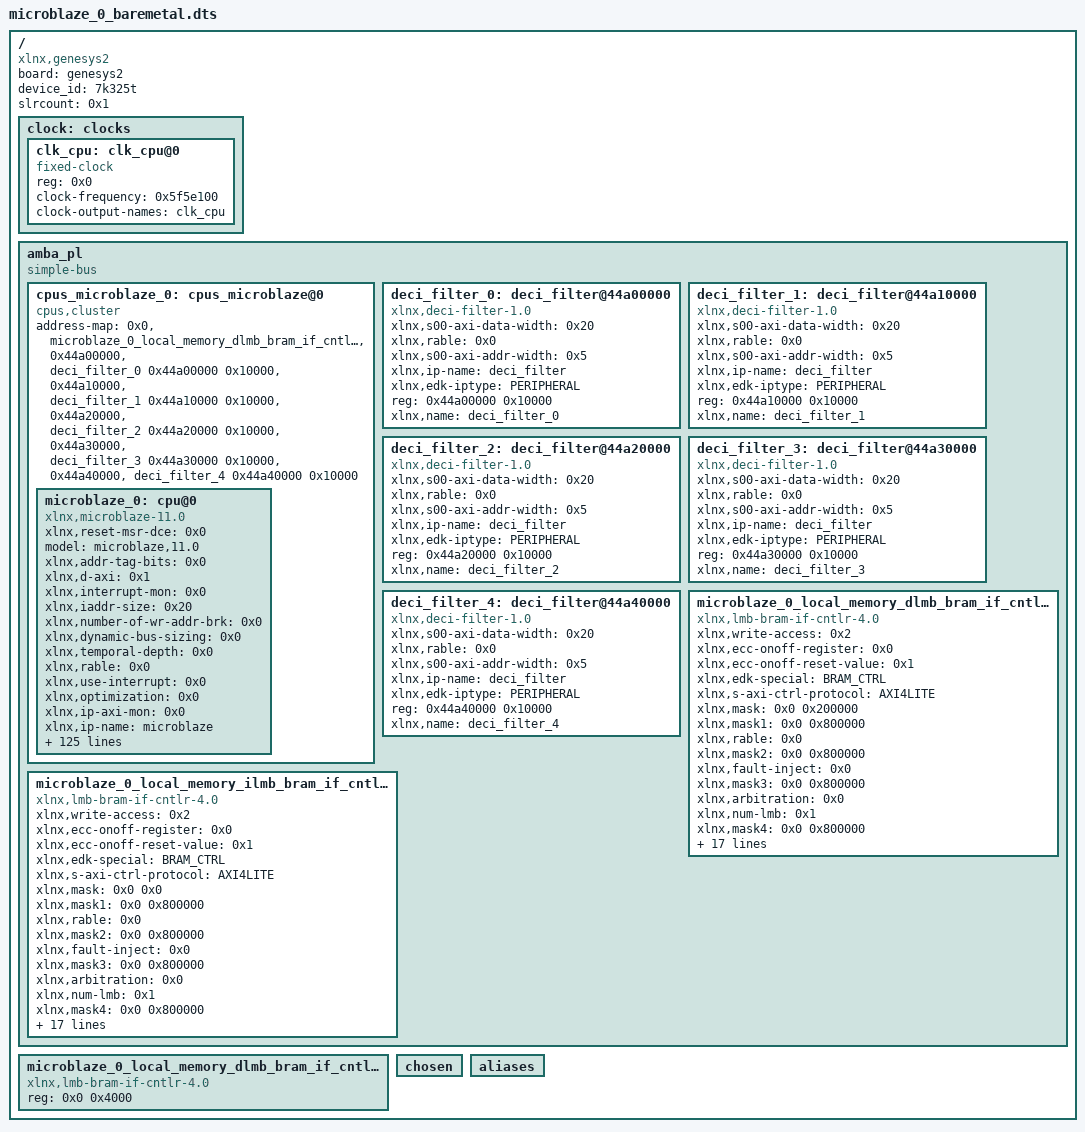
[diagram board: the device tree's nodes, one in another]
/dts-v1/;

/ {
        board = "genesys2";
        compatible = "xlnx,genesys2";
        device_id = "7k325t";
        #address-cells = <0x1>;
        #size-cells = <0x1>;
        slrcount = <0x1>;

        clock: clocks {
                #address-cells = <0x1>;
                #size-cells = <0x0>;
                phandle = <0x8>;

                clk_cpu: clk_cpu@0 {
                        compatible = "fixed-clock";
                        reg = <0x0>;
                        clock-frequency = <0x5f5e100>;
                        clock-output-names = "clk_cpu";
                        #clock-cells = <0x0>;
                        phandle = <0x9>;
                };
        };

        amba_pl: amba_pl {
                ranges;
                compatible = "simple-bus";
                #address-cells = <0x1>;
                #size-cells = <0x1>;
                phandle = <0x7>;

                cpus_microblaze_0: cpus_microblaze@0 {
                        #cpu-mask-cells = <0x1>;
                        compatible = "cpus,cluster";
                        address-map = <0x0 &microblaze_0_local_memory_dlmb_bram_if_cntlr_memory 0x0 0x4000>,
                         <0x44a00000 &deci_filter_0 0x44a00000 0x10000>,
                         <0x44a10000 &deci_filter_1 0x44a10000 0x10000>,
                         <0x44a20000 &deci_filter_2 0x44a20000 0x10000>,
                         <0x44a30000 &deci_filter_3 0x44a30000 0x10000>,
                         <0x44a40000 &deci_filter_4 0x44a40000 0x10000>;
                        #ranges-address-cells = <0x1>;
                        #ranges-size-cells = <0x1>;
                        phandle = <0xa>;

                        microblaze_0: cpu@0 {
                                xlnx,reset-msr-dce = <0x0>;
                                model = "microblaze,11.0";
                                xlnx,addr-tag-bits = <0x0>;
                                xlnx,d-axi = <0x1>;
                                xlnx,interrupt-mon = <0x0>;
                                xlnx,iaddr-size = <0x20>;
                                xlnx,number-of-wr-addr-brk = <0x0>;
                                xlnx,dynamic-bus-sizing = <0x0>;
                                xlnx,temporal-depth = <0x0>;
                                xlnx,rable = <0x0>;
                                xlnx,use-interrupt = <0x0>;
                                xlnx,optimization = <0x0>;
                                xlnx,ip-axi-mon = <0x0>;
                                xlnx,ip-name = "microblaze";
                                d-cache-highaddr = <0x3fffffff>;
                                xlnx,dcache-force-tag-lutram = <0x0>;
                                xlnx,pc-width = <0x20>;
                                xlnx,interrupt-is-edge = <0x0>;
                                reg = <0x0>;
                                xlnx,async-interrupt = <0x1>;
                                xlnx,use-mmu = <0x0>;
                                xlnx,reset-msr-ee = <0x0>;
                                xlnx,icache-victims = <0x0>;
                                xlnx,use-reorder-instr = <0x1>;
                                xlnx,d-lmb-mon = <0x0>;
                                xlnx,d-lmb-protocol = <0x0>;
                                xlnx,ill-opcode-exception = <0x0>;
                                xlnx,dcache-always-used = <0x1>;
                                xlnx,use-div = <0x0>;
                                xlnx,dc-axi-mon = <0x0>;
                                xlnx,debug-trace-async-reset = <0x0>;
                                xlnx,trace = <0x0>;
                                xlnx,part = "xc7k325tffg900-2";
                                i-cache-baseaddr = <0x0>;
                                xlnx,use-config-reset = <0x0>;
                                xlnx,pvr = <0x0>;
                                xlnx,i-lmb-mon = <0x0>;
                                xlnx,dcache-byte-size = <0x2000>;
                                xlnx,fault-tolerant = <0x0>;
                                xlnx,family = "kintex7";
                                compatible = "xlnx,microblaze-11.0", "xlnx,microblaze";
                                xlnx,data-size = <0x20>;
                                xlnx,mmu-zones = <0x10>;
                                xlnx,debug-trace-size = <0x2000>;
                                xlnx,mmu-privileged-instr = <0x0>;
                                xlnx,enable-discrete-ports = <0x0>;
                                d-cache-line-size = <0x10>;
                                xlnx,d-lmb = <0x1>;
                                xlnx,sco = <0x0>;
                                xlnx,reset-msr-eip = <0x0>;
                                clock-frequency = <0x5f5e100>;
                                xlnx,debug-interface = <0x0>;
                                xlnx,use-ext-brk = <0x0>;
                                xlnx,daddr-size = <0x20>;
                                xlnx,debug-enabled = <0x1>;
                                xlnx,reset-msr-ice = <0x0>;
                                xlnx,num-sync-ff-dbg-trace-clk = <0x2>;
                                xlnx,i-lmb-protocol = <0x0>;
                                xlnx,endianness = <0x1>;
                                xlnx,fsl-exception = <0x0>;
                                i-cache-line-size = <0x10>;
                                xlnx,use-extended-fsl-instr = <0x0>;
                                xlnx,reset-msr = <0x0>;
                                xlnx,dp-axi-mon = <0x0>;
                                xlnx,branch-target-cache-size = <0x0>;
                                xlnx,dcache-use-writeback = <0x0>;
                                xlnx,div-zero-exception = <0x0>;
                                xlnx,mmu-tlb-access = <0x3>;
                                bus-handle = <0x7>;
                                xlnx,cache-byte-size = <0x2000>;
                                xlnx,pvr-user2 = <0x0>;
                                xlnx,opcode-0x0-illegal = <0x0>;
                                xlnx,icache-line-len = <0x4>;
                                xlnx,ecc-use-ce-exception = <0x0>;
                                xlnx,base-vectors = <0x0 0x0>;
                                xlnx,use-dcache = <0x0>;
                                xlnx,use-barrel = <0x0>;
                                xlnx,reset-msr-bip = <0x0>;
                                xlnx,edk-special = "microblaze";
                                xlnx,allow-dcache-wr = <0x1>;
                                xlnx,addr-size = <0x20>;
                                xlnx,debug-external-trace = <0x0>;
                                xlnx,piaddr-size = <0x20>;
                                i-cache-highaddr = <0x3fffffff>;
                                xlnx,num-sync-ff-clk-debug = <0x2>;
                                xlnx,debug-event-counters = <0x5>;
                                xlnx,fpu-exception = <0x0>;
                                xlnx,allow-icache-wr = <0x1>;
                                xlnx,i-axi = <0x0>;
                                xlnx,g-use-exceptions = <0x0>;
                                xlnx,icache-streams = <0x0>;
                                xlnx,g-template-list = <0x0>;
                                xlnx,dcache-line-len = <0x4>;
                                xlnx,num-sync-ff-clk = <0x2>;
                                xlnx,use-stack-protection = <0x0>;
                                xlnx,use-hw-mul = <0x0>;
                                xlnx,num-sync-ff-dbg-clk = <0x1>;
                                xlnx,interconnect = <0x2>;
                                xlnx,edk-iptype = "PROCESSOR";
                                i-cache-size = <0x2000>;
                                xlnx,debug-latency-counters = <0x1>;
                                xlnx,use-fpu = <0x0>;
                                xlnx,reset-msr-ie = <0x0>;
                                xlnx,edge-is-positive = <0x1>;
                                xlnx,use-pcmp-instr = <0x0>;
                                xlnx,use-icache = <0x0>;
                                d-cache-size = <0x2000>;
                                xlnx,async-wakeup = <0x3>;
                                xlnx,use-non-secure = <0x0>;
                                xlnx,dcache-addr-tag = <0x0>;
                                xlnx,number-of-rd-addr-brk = <0x0>;
                                d-cache-baseaddr = <0x0>;
                                xlnx,area-optimized = <0x0>;
                                xlnx,avoid-primitives = <0x0>;
                                xlnx,lockstep-slave = <0x0>;
                                xlnx,use-ext-nm-brk = <0x0>;
                                xlnx,instr-size = <0x20>;
                                xlnx,icache-always-used = <0x1>;
                                xlnx,i-lmb = <0x1>;
                                xlnx,mmu-dtlb-size = <0x4>;
                                xlnx,lockstep-select = <0x0>;
                                xlnx,lmb-data-size = <0x20>;
                                xlnx,ic-axi-mon = <0x0>;
                                xlnx,num-sync-ff-clk-irq = <0x1>;
                                xlnx,fsl-links = <0x0>;
                                timebase-frequency = <0x5f5e100>;
                                xlnx,icache-force-tag-lutram = <0x0>;
                                xlnx,dcache-data-width = <0x0>;
                                xlnx,dcache-victims = <0x0>;
                                xlnx,use-branch-target-cache = <0x0>;
                                xlnx,debug-profile-size = <0x0>;
                                xlnx,unaligned-exceptions = <0x0>;
                                xlnx,lockstep-master = <0x0>;
                                xlnx,freq = <0x5f5e100>;
                                xlnx,number-of-pc-brk = <0x1>;
                                xlnx,mmu-itlb-size = <0x2>;
                                xlnx,imprecise-exceptions = <0x0>;
                                xlnx,use-msr-instr = <0x0>;
                                xlnx,icache-data-width = <0x0>;
                                xlnx,debug-counter-width = <0x20>;
                                phandle = <0xb>;
                        };
                };

                deci_filter_0: deci_filter@44a00000 {
                        xlnx,s00-axi-data-width = <0x20>;
                        xlnx,rable = <0x0>;
                        compatible = "xlnx,deci-filter-1.0";
                        status = "okay";
                        xlnx,s00-axi-addr-width = <0x5>;
                        xlnx,ip-name = "deci_filter";
                        xlnx,edk-iptype = "PERIPHERAL";
                        reg = <0x44a00000 0x10000>;
                        xlnx,name = "deci_filter_0";
                        phandle = <0x2>;
                };

                deci_filter_1: deci_filter@44a10000 {
                        xlnx,s00-axi-data-width = <0x20>;
                        xlnx,rable = <0x0>;
                        compatible = "xlnx,deci-filter-1.0";
                        status = "okay";
                        xlnx,s00-axi-addr-width = <0x5>;
                        xlnx,ip-name = "deci_filter";
                        xlnx,edk-iptype = "PERIPHERAL";
                        reg = <0x44a10000 0x10000>;
                        xlnx,name = "deci_filter_1";
                        phandle = <0x3>;
                };

                deci_filter_2: deci_filter@44a20000 {
                        xlnx,s00-axi-data-width = <0x20>;
                        xlnx,rable = <0x0>;
                        compatible = "xlnx,deci-filter-1.0";
                        status = "okay";
                        xlnx,s00-axi-addr-width = <0x5>;
                        xlnx,ip-name = "deci_filter";
                        xlnx,edk-iptype = "PERIPHERAL";
                        reg = <0x44a20000 0x10000>;
                        xlnx,name = "deci_filter_2";
                        phandle = <0x4>;
                };

                deci_filter_3: deci_filter@44a30000 {
                        xlnx,s00-axi-data-width = <0x20>;
                        xlnx,rable = <0x0>;
                        compatible = "xlnx,deci-filter-1.0";
                        status = "okay";
                        xlnx,s00-axi-addr-width = <0x5>;
                        xlnx,ip-name = "deci_filter";
                        xlnx,edk-iptype = "PERIPHERAL";
                        reg = <0x44a30000 0x10000>;
                        xlnx,name = "deci_filter_3";
                        phandle = <0x5>;
                };

                deci_filter_4: deci_filter@44a40000 {
                        xlnx,s00-axi-data-width = <0x20>;
                        xlnx,rable = <0x0>;
                        compatible = "xlnx,deci-filter-1.0";
                        status = "okay";
                        xlnx,s00-axi-addr-width = <0x5>;
                        xlnx,ip-name = "deci_filter";
                        xlnx,edk-iptype = "PERIPHERAL";
                        reg = <0x44a40000 0x10000>;
                        xlnx,name = "deci_filter_4";
                        phandle = <0x6>;
                };

                microblaze_0_local_memory_dlmb_bram_if_cntlr: lmb_bram_if_cntlr@0 {
                        xlnx,write-access = <0x2>;
                        compatible = "xlnx,lmb-bram-if-cntlr-4.0";
                        xlnx,ecc-onoff-register = <0x0>;
                        xlnx,ecc-onoff-reset-value = <0x1>;
                        xlnx,edk-special = "BRAM_CTRL";
                        xlnx,s-axi-ctrl-protocol = "AXI4LITE";
                        xlnx,mask = <0x0 0x200000>;
                        xlnx,mask1 = <0x0 0x800000>;
                        xlnx,rable = <0x0>;
                        xlnx,mask2 = <0x0 0x800000>;
                        xlnx,fault-inject = <0x0>;
                        xlnx,mask3 = <0x0 0x800000>;
                        xlnx,arbitration = <0x0>;
                        xlnx,num-lmb = <0x1>;
                        xlnx,mask4 = <0x0 0x800000>;
                        reg = <0x0 0x4000>;
                        xlnx,s-axi-ctrl-addr-width = <0x20>;
                        xlnx,mask5 = <0x0 0x800000>;
                        xlnx,ecc-status-registers = <0x0>;
                        xlnx,mask6 = <0x0 0x800000>;
                        xlnx,lmb-protocol = <0x0>;
                        xlnx,ce-counter-width = <0x0>;
                        xlnx,mask7 = <0x0 0x800000>;
                        xlnx,ecc = <0x0>;
                        xlnx,lmb-dwidth = <0x20>;
                        xlnx,interconnect = <0x0>;
                        xlnx,ce-failing-registers = <0x0>;
                        xlnx,edk-iptype = "PERIPHERAL";
                        xlnx,ue-failing-registers = <0x0>;
                        xlnx,s-axi-ctrl-data-width = <0x20>;
                        xlnx,bram-awidth = <0x20>;
                        xlnx,lmb-awidth = <0x20>;
                        phandle = <0xc>;
                };

                microblaze_0_local_memory_ilmb_bram_if_cntlr: lmb_bram_if_cntlr@1 {
                        xlnx,write-access = <0x2>;
                        compatible = "xlnx,lmb-bram-if-cntlr-4.0";
                        xlnx,ecc-onoff-register = <0x0>;
                        xlnx,ecc-onoff-reset-value = <0x1>;
                        xlnx,edk-special = "BRAM_CTRL";
                        xlnx,s-axi-ctrl-protocol = "AXI4LITE";
                        xlnx,mask = <0x0 0x0>;
                        xlnx,mask1 = <0x0 0x800000>;
                        xlnx,rable = <0x0>;
                        xlnx,mask2 = <0x0 0x800000>;
                        xlnx,fault-inject = <0x0>;
                        xlnx,mask3 = <0x0 0x800000>;
                        xlnx,arbitration = <0x0>;
                        xlnx,num-lmb = <0x1>;
                        xlnx,mask4 = <0x0 0x800000>;
                        reg = <0x0 0x4000>;
                        xlnx,s-axi-ctrl-addr-width = <0x20>;
                        xlnx,mask5 = <0x0 0x800000>;
                        xlnx,ecc-status-registers = <0x0>;
                        xlnx,mask6 = <0x0 0x800000>;
                        xlnx,lmb-protocol = <0x0>;
                        xlnx,ce-counter-width = <0x0>;
                        xlnx,mask7 = <0x0 0x800000>;
                        xlnx,ecc = <0x0>;
                        xlnx,lmb-dwidth = <0x20>;
                        xlnx,interconnect = <0x0>;
                        xlnx,ce-failing-registers = <0x0>;
                        xlnx,edk-iptype = "PERIPHERAL";
                        xlnx,ue-failing-registers = <0x0>;
                        xlnx,s-axi-ctrl-data-width = <0x20>;
                        xlnx,bram-awidth = <0x20>;
                        xlnx,lmb-awidth = <0x20>;
                        phandle = <0xd>;
                };
        };

        microblaze_0_local_memory_dlmb_bram_if_cntlr_memory: memory@0 {
                compatible = "xlnx,lmb-bram-if-cntlr-4.0";
                device_type = "memory";
                reg = <0x0 0x4000>;
                phandle = <0x1>;
        };

        chosen {
        };

        aliases {
        };

        __symbols__ {
                clock = "/clocks";
                clk_cpu = "/clocks/clk_cpu@0";
                amba_pl = "/amba_pl";
                cpus_microblaze_0 = "/amba_pl/cpus_microblaze@0";
                microblaze_0 = "/amba_pl/cpus_microblaze@0/cpu@0";
                deci_filter_0 = "/amba_pl/deci_filter@44a00000";
                deci_filter_1 = "/amba_pl/deci_filter@44a10000";
                deci_filter_2 = "/amba_pl/deci_filter@44a20000";
                deci_filter_3 = "/amba_pl/deci_filter@44a30000";
                deci_filter_4 = "/amba_pl/deci_filter@44a40000";
                microblaze_0_local_memory_dlmb_bram_if_cntlr = "/amba_pl/lmb_bram_if_cntlr@0";
                microblaze_0_local_memory_ilmb_bram_if_cntlr = "/amba_pl/lmb_bram_if_cntlr@1";
                microblaze_0_local_memory_dlmb_bram_if_cntlr_memory = "/memory@0";
        };
};
